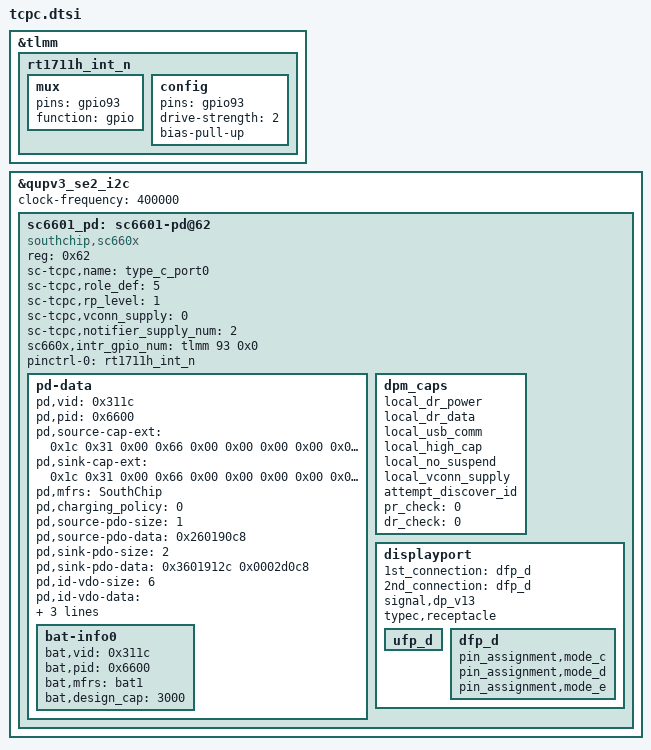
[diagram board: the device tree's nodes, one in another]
&tlmm {
	/* GPIO_93 : CHG_PD_INT_N */
	rt1711h_int_n: rt1711h_int_n {
		mux {
			pins = "gpio93";
			function = "gpio";
		};
		config {
			pins = "gpio93";
			drive-strength = <2>;
			bias-pull-up;
		};
	};
};

&qupv3_se2_i2c {
	status = "okay";
	clock-frequency = <400000>;

	sc6601_pd: sc6601-pd@62{
		compatible = "southchip,sc660x";
		reg = <0x62>;
		status = "okay";
		sc-tcpc,name = "type_c_port0"; /* tcpc_device's name */
		sc-tcpc,role_def = <5>; /* 0: Unknown, 1: SNK, 2: SRC */
					/* 3: DRP, 4: Try.SRC, 5: Try.SNK */
		sc-tcpc,rp_level = <1>; /* 0: Default, 1: 1.5, 2: 3.0 */
		sc-tcpc,vconn_supply  = <0>;  /* 0: Never, 1: Always, */
					      /* 2: EMarkOnly, 3: StartOnly */
		sc-tcpc,notifier_supply_num = <2>;
		sc660x,intr_gpio_num = <&tlmm 93 0x0>;
		pinctrl-names = "default";
		pinctrl-0 = <&rt1711h_int_n>;
		pd-data {
			pd,vid = <0x311c>;
			pd,pid = <0x6600>;
			pd,source-cap-ext = /bits/ 8 <0x1c 0x31 0x00 0x66
						      0x00 0x00 0x00 0x00
						      0x00 0x00 0x00 0x00
						      0x00 0x00 0x00 0x00
						      0x00 0x00 0x00 0x00
						      0x00 0x00 0x01 0x07
						      0x00>;
			pd,sink-cap-ext = /bits/ 8 <0x1c 0x31 0x00 0x66
							   0x00 0x00 0x00 0x00
							   0x01 0x00 0x00 0x00
							   0x00 0x00 0x00 0x00
							   0x01 0x00 0x00 0x00
							   0x00 0x00 0x00 0x00>;
			pd,mfrs = "SouthChip";

			/*
			 *	VSAFE5V = 0, MAX_POWER = 1, CUSTOM = 2,
			 *	MAX_POWER_LV = 0x21, MAX_POWER_LVIC = 0x31
			 *	MAX_POWER_HV = 0x41, MAX_POWER_HVIC = 0x51
			 */
			pd,charging_policy = <0>;

			/*
			 * Fixed 5V, 500 mA <0x00019032>
			 * Fixed 5V, 1A <0x00019064>
			 * Fixed 5V, 2A <0x000190c8>
			 * Fixed 5V, 3A <0x0001912c>
			 * Fixed 9V, 500 mA <0x0002d032>
			 * Fixed 9V, 1A <0x0002d064>
			 * Fixed 9V, 2A <0x0002d0c8>
			 * Fixed 9V, 3A <0x0002d12c>
			 * Variable 5-9V, 1A <0x8642d064>
			 * Variable 5-9V, 2A <0x8642d0c8>
			 * Variable 5-9V, 3A <0x8642d12c>
			 * PPS 3V~5.9V, 3A <0xC0761E3C>
			 */
			pd,source-pdo-size = <1>;
			/* Fixed 5V,2A */
			pd,source-pdo-data = <0x260190c8>;
			//pd,source-18w-pdo-size = <2>;
			/* Fixed 5V,1A 9V,1.6A*/
			//pd,source-18w-pdo-data = <0x20019064 0x2002d0A0>;

			pd,sink-pdo-size = <2>;
			pd,sink-pdo-data = <0x3601912c 0x0002d0c8>;
			/*0110 1110 0011 0010
			 * No DP, host + device
			 *	pd,id-vdo-size = <6>;
			 *	pd,id-vdo-data = <0xd14029cf 0x0 0x17110000
						  0x61000000 0x0 0x41000000>;
			 * With DP
			 *	pd,id-vdo-size = <6>;
			 *	pd,id-vdo-data = <0xd54029cf 0x0 0x17110000
						  0x61000000 0x0 0x41000000>;
			 */

			pd,id-vdo-size = <6>;
			pd,id-vdo-data = <0xd140311c 0x0 0x66000000
						  0x61000000 0x0 0x41000000>;

			bat,nr = <1>;
			pd,country_nr = <0>;

			bat-info0 {
				bat,vid = <0x311c>;
				bat,pid = <0x6600>;
				bat,mfrs = "bat1";
				bat,design_cap = <3000>;
			};

		};
		dpm_caps {
			local_dr_power;
			local_dr_data;
			//local_ext_power;
			local_usb_comm;
			//local_usb_suspend;
			local_high_cap;
			//local_give_back;
			local_no_suspend;
			local_vconn_supply;

			//attempt_discover_cable_dfp;
			//attempt_enter_dp_mode;
			//attempt_discover_cable;
			attempt_discover_id;
			//attempt_discover_svid;

			/* 0: disable, 1: prefer_snk, 2: prefer_src */
			pr_check = <0>;
			//pr_reject_as_source;
			//pr_reject_as_sink;
			//pr_check_gp_source;
			//pr_check_gp_sink;

			/* 0: disable, 1: prefer_ufp, 2: prefer_dfp */
			dr_check = <0>;
			//dr_reject_as_dfp;
			//dr_reject_as_ufp;
		};
		displayport {
			/* connection type = "both", "ufp_d", "dfp_d" */
			1st_connection = "dfp_d";
			2nd_connection = "dfp_d";
			signal,dp_v13;
			//signal,dp_gen2;
			//usbr20_not_used;
			typec,receptacle;
			ufp_d {
				//pin_assignment,mode_a;
				//pin_assignment,mode_b;
				//pin_assignment,mode_c;
				//pin_assignment,mode_d;
				//pin_assignment,mode_e;
			};
			dfp_d {
				//pin_assignment,mode_a;
				//pin_assignment,mode_b;
				pin_assignment,mode_c;
				pin_assignment,mode_d;
				pin_assignment,mode_e;
				//pin_assignment,mode_f;
			};
		};
	};
};
